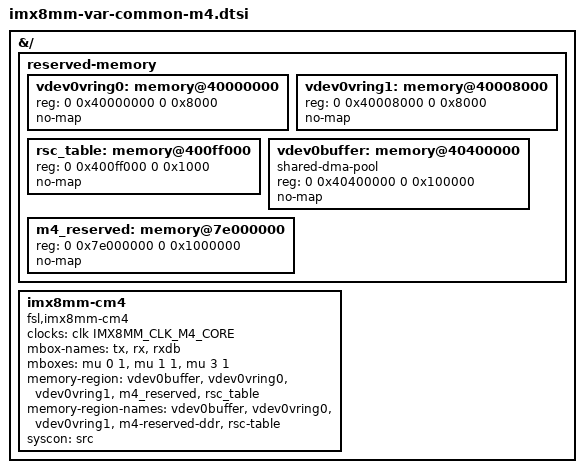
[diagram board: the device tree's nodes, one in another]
// SPDX-License-Identifier: (GPL-2.0+ OR MIT)
/*
 * Common Cortex-M4 configuration for Variscite i.MX8M Mini modules
 *
 * Link: https://www.variscite.com/
 *
 * Copyright (C) 2026 Variscite Ltd. - https://www.variscite.com/
 *
 */

#include <dt-bindings/clock/imx8mm-clock.h>

&{/} {
	#address-cells = <2>;
	#size-cells = <2>;

	reserved-memory {
		#address-cells = <2>;
		#size-cells = <2>;
		ranges;

		vdev0vring0: memory@40000000 {
			reg = <0 0x40000000 0 0x8000>;
			no-map;
		};

		vdev0vring1: memory@40008000 {
			reg = <0 0x40008000 0 0x8000>;
			no-map;
		};

		rsc_table: memory@400ff000 {
			reg = <0 0x400ff000 0 0x1000>;
			no-map;
		};

		vdev0buffer: memory@40400000 {
			compatible = "shared-dma-pool";
			reg = <0 0x40400000 0 0x100000>;
			no-map;
		};

		m4_reserved: memory@7e000000 {
			reg = <0 0x7e000000 0 0x1000000>;
			no-map;
		};
	};

	imx8mm-cm4 {
		compatible = "fsl,imx8mm-cm4";
		clocks = <&clk IMX8MM_CLK_M4_CORE>;
		mbox-names = "tx", "rx", "rxdb";
		mboxes = <&mu 0 1
			  &mu 1 1
			  &mu 3 1>;
		memory-region = <&vdev0buffer>, <&vdev0vring0>, <&vdev0vring1>,
				<&m4_reserved>, <&rsc_table>;
		memory-region-names = "vdev0buffer", "vdev0vring0", "vdev0vring1",
				      "m4-reserved-ddr", "rsc-table";
		syscon = <&src>;
	};
};
